VERSION ""

NS_ :

BS_:

BU_:

BO_ 3221225472 VECTOR__INDEPENDENT_SIG_MSG: 0 Vector__XXX
 SG_ current_filter_1 : 0|16@1+ (0.1,-600) [800|4294966496] "" Vector__XXX
 SG_ bms_unique_key_byte7 : 0|8@1+ (1,0) [0|255] "" Vector__XXX
 SG_ bms_unique_key_byte6 : 0|8@1+ (1,0) [0|255] "" Vector__XXX
 SG_ bms_unique_key_byte5 : 0|8@1+ (1,0) [0|255] "" Vector__XXX
 SG_ bms_unique_key_byte4 : 0|8@1+ (1,0) [0|255] "" Vector__XXX
 SG_ bms_unique_key_byte3 : 0|8@1+ (1,0) [0|255] "" Vector__XXX
 SG_ bms_unique_key_byte2 : 0|8@1+ (1,0) [0|255] "" Vector__XXX
 SG_ bms_unique_key_byte1 : 0|8@1+ (1,0) [0|255] "" Vector__XXX
 SG_ bms_unique_key_byte0 : 0|8@1+ (1,0) [0|255] "" Vector__XXX
 SG_ battery_unique_key_byte7 : 0|8@1+ (1,0) [0|255] "" Vector__XXX
 SG_ battery_unique_key_byte6 : 0|8@1+ (1,0) [0|255] "" Vector__XXX
 SG_ battery_unique_key_byte5 : 0|8@1+ (1,0) [0|255] "" Vector__XXX
 SG_ battery_unique_key_byte4 : 0|8@1+ (1,0) [0|255] "" Vector__XXX
 SG_ battery_unique_key_byte3 : 0|8@1+ (1,0) [0|255] "" Vector__XXX
 SG_ battery_unique_key_byte2 : 0|8@1+ (1,0) [0|255] "" Vector__XXX
 SG_ battery_unique_key_byte1 : 0|8@1+ (1,0) [0|255] "" Vector__XXX
 SG_ battery_unique_key_byte0 : 0|8@1+ (1,0) [0|255] "" Vector__XXX
 SG_ slow_charger_state_bms : 0|8@1+ (1,0) [0|255] "" Vector__XXX
 SG_ bms_ota_soc : 0|16@1+ (0.01,0) [0|655.35] "" Vector__XXX
 SG_ hw_minor : 0|8@1+ (1,0) [0|255] "" Vector__XXX
 SG_ hw_major : 0|8@1+ (1,0) [0|255] "" Vector__XXX
 SG_ fw_patch : 0|8@1+ (1,0) [0|255] "" Vector__XXX
 SG_ fw_oem_variant : 0|8@1+ (1,0) [0|255] "" Vector__XXX
 SG_ fw_oem_patch : 0|8@1+ (1,0) [0|255] "" Vector__XXX
 SG_ fw_oem_lookup : 0|8@1+ (1,0) [0|255] "" Vector__XXX
 SG_ fw_minor : 0|8@1+ (1,0) [0|255] "" Vector__XXX
 SG_ fw_major : 0|8@1+ (1,0) [0|255] "" Vector__XXX
 SG_ min_cell_temp_bms : 0|16@1+ (0.01,-100) [150|4294967246] "" Vector__XXX
 SG_ max_cell_temp_bms : 0|16@1+ (0.01,-100) [150|4294967246] "" Vector__XXX
 SG_ min_cell_voltage_bms : 0|16@1+ (0.0001,0) [0|6.5535] "" Vector__XXX
 SG_ max_cell_voltage_bms : 0|16@1+ (0.0001,0) [0|6.5535] "" Vector__XXX
 SG_ tp_alarm : 0|8@1+ (1,0) [0|255] "" Vector__XXX
 SG_ bms_current_bms : 0|16@1+ (0.1,-600) [800|4294966496] "" Vector__XXX
 SG_ dyna_out_accept_2 : 0|8@1+ (1,0) [0|255] "" Vector__XXX
 SG_ dyna_out_accept : 0|8@1+ (1,0) [0|255] "" Vector__XXX
 SG_ dyna_out_2 : 0|16@1+ (1,0) [0|255] "" Vector__XXX
 SG_ stecom_signal_6 : 0|8@1+ (1,0) [0|255] "" Vector__XXX
 SG_ stecom_signal_5 : 0|8@1+ (1,0) [0|255] "" Vector__XXX
 SG_ stecom_signal_4 : 0|8@1+ (1,0) [0|255] "" Vector__XXX
 SG_ stecom_signal_3 : 0|8@1+ (1,0) [0|255] "" Vector__XXX
 SG_ dyna_out_1 : 0|8@1+ (1,0) [0|255] "" Vector__XXX
 SG_ stecom_signal_1 : 0|8@1+ (1,0) [0|255] "" Vector__XXX
 SG_ bms_fault_2 : 0|16@1+ (1,0) [0|65535] "" Vector__XXX
 SG_ bms_fault_1 : 0|16@1+ (1,0) [0|65535] "" Vector__XXX
 SG_ battery_capacity : 0|16@1+ (0.001,0) [0|65.535] "" Vector__XXX
 SG_ used_energy : 0|16@1+ (0.001,0) [0|65.535] "" Vector__XXX
 SG_ io_status : 0|16@1+ (1,0) [0|65535] "" Vector__XXX
 SG_ odo_low : 0|16@1+ (1,0) [0|65535] "" Vector__XXX
 SG_ odo_high : 0|16@1+ (1,0) [0|65535] "" Vector__XXX
 SG_ vehicle_speed : 0|16@1+ (0.01,0) [0|655.35] "" Vector__XXX
 SG_ brake_pedal_position : 0|16@1+ (0.01,0) [0|655.35] "" Vector__XXX
 SG_ throttle_position : 0|16@1+ (0.01,0) [0|655.35] "" Vector__XXX
 SG_ battery_current : 0|16@1+ (0.01,-300) [355.55|4294966996] "" Vector__XXX
 SG_ battery_voltage : 0|16@1+ (0.01,0) [0|655.35] "" Vector__XXX
 SG_ fault_code_1 : 0|16@1+ (1,0) [0|65535] "" Vector__XXX
 SG_ fault_code_2 : 0|16@1+ (1,0) [0|65535] "" Vector__XXX
 SG_ on_off_slow_charger : 0|1@1+ (1,0) [0|1] "" Vector__XXX
 SG_ slow_charger_set_8_bms : 0|8@1+ (1,0) [0|255] "" Vector__XXX
 SG_ slow_charger_set_7_bms : 0|8@1+ (1,0) [0|255] "" Vector__XXX
 SG_ slow_charger_set_6_bms : 0|8@1+ (1,0) [0|255] "" Vector__XXX
 SG_ slow_charger_Set_5_bms : 0|8@1+ (1,0) [0|255] "" Vector__XXX
 SG_ slow_charger_set_4_bms : 0|8@1+ (1,0) [0|255] "" Vector__XXX
 SG_ slow_charger_set_3_bms : 0|8@1+ (1,0) [0|255] "" Vector__XXX
 SG_ slow_charger_set_2_bms : 0|8@1+ (1,0) [0|255] "" Vector__XXX
 SG_ slow_charger_set_1_bms : 0|8@1+ (1,0) [0|255] "" Vector__XXX

BO_ 548 ticm_msg15: 8 Vector__XXX
 SG_ sig_bms_fw_version : 7|16@0+ (1,0) [0|65535] "" Vector__XXX

BO_ 547 ticm_msg14: 8 Vector__XXX
 SG_ sig_bms_hw_version : 7|16@0+ (1,0) [0|65535] "" Vector__XXX

BO_ 526 ticm_msg13: 8 Vector__XXX
 SG_ sig_error_bit : 47|8@0+ (1,0) [0|255] "" Vector__XXX
 SG_ tp_alarm : 7|8@0+ (1,0) [0|255] "" Vector__XXX

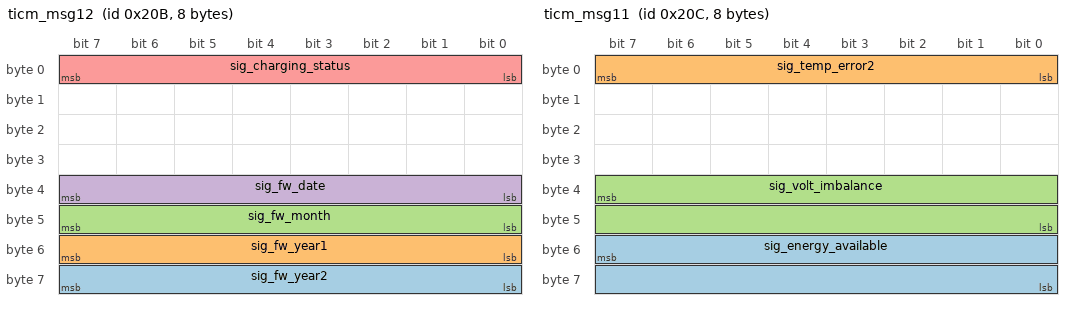
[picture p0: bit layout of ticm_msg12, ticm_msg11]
BO_ 523 ticm_msg12: 8 Vector__XXX
 SG_ sig_fw_year2 : 63|8@0+ (1,0) [0|255] "" Vector__XXX
 SG_ sig_fw_year1 : 55|8@0+ (1,0) [0|255] "" Vector__XXX
 SG_ sig_fw_month : 47|8@0+ (1,0) [0|255] "" Vector__XXX
 SG_ sig_fw_date : 39|8@0+ (1,0) [0|0] "" Vector__XXX
 SG_ sig_charging_status : 7|8@0+ (1,0) [0|255] "" Vector__XXX

BO_ 524 ticm_msg11: 8 Vector__XXX
 SG_ sig_energy_available : 55|16@0+ (1,0) [0|65535] "" Vector__XXX
 SG_ sig_temp_error2 : 7|8@0+ (1,0) [0|255] "" Vector__XXX
 SG_ sig_volt_imbalance : 39|16@0+ (1,0) [0|65535] "" Vector__XXX

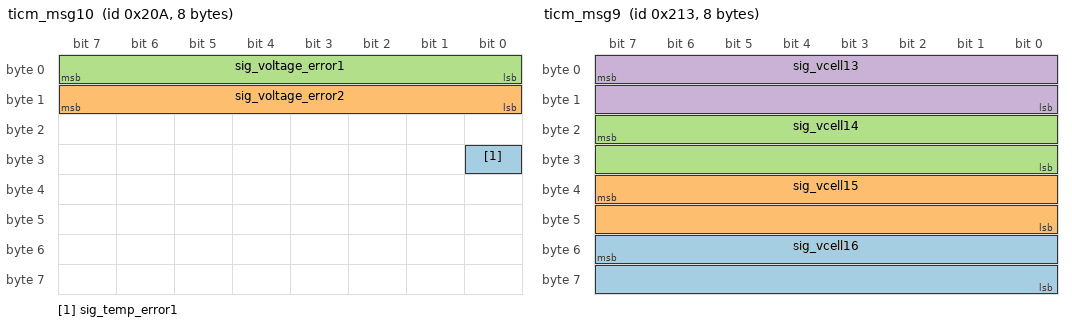
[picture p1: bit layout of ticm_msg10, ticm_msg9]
BO_ 522 ticm_msg10: 8 Vector__XXX
 SG_ sig_temp_error1 : 24|1@0+ (1,0) [0|1] "" Vector__XXX
 SG_ sig_voltage_error2 : 15|8@0+ (1,0) [0|255] "" Vector__XXX
 SG_ sig_voltage_error1 : 7|8@0+ (1,0) [0|255] "" Vector__XXX

BO_ 531 ticm_msg9: 8 Vector__XXX
 SG_ sig_vcell16 : 55|16@0+ (0.001,0) [0|65.535] "" Vector__XXX
 SG_ sig_vcell15 : 39|16@0+ (0.001,0) [0|65.535] "" Vector__XXX
 SG_ sig_vcell14 : 23|16@0+ (0.001,0) [0|65.535] "" Vector__XXX
 SG_ sig_vcell13 : 7|16@0+ (0.001,0) [0|65.535] "" Vector__XXX

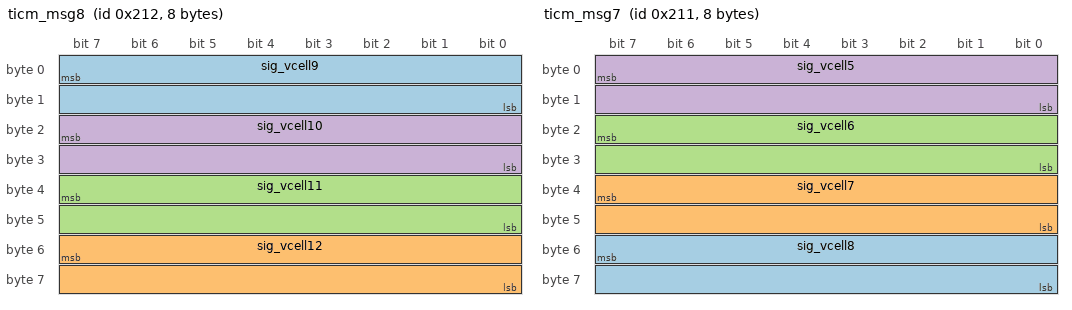
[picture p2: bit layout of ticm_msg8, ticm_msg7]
BO_ 530 ticm_msg8: 8 Vector__XXX
 SG_ sig_vcell9 : 7|16@0+ (0.001,0) [0|65.535] "" Vector__XXX
 SG_ sig_vcell12 : 55|16@0+ (0.001,0) [0|65.535] "" Vector__XXX
 SG_ sig_vcell11 : 39|16@0+ (0.001,0) [0|65.535] "" Vector__XXX
 SG_ sig_vcell10 : 23|16@0+ (0.001,0) [0|65.535] "" Vector__XXX

BO_ 529 ticm_msg7: 8 Vector__XXX
 SG_ sig_vcell8 : 55|16@0+ (0.001,0) [0|65.535] "" Vector__XXX
 SG_ sig_vcell7 : 39|16@0+ (0.001,0) [0|65.535] "" Vector__XXX
 SG_ sig_vcell6 : 23|16@0+ (0.001,0) [0|65.535] "" Vector__XXX
 SG_ sig_vcell5 : 7|16@0+ (0.001,0) [0|65.535] "" Vector__XXX

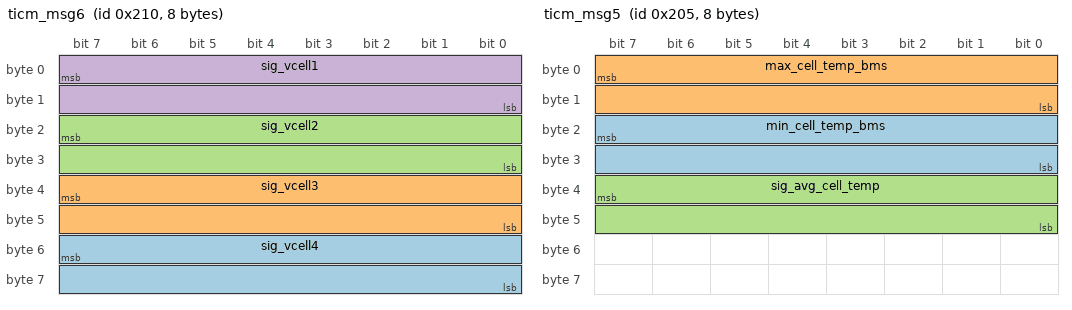
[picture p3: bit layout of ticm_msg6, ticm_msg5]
BO_ 528 ticm_msg6: 8 Vector__XXX
 SG_ sig_vcell4 : 55|16@0+ (0.001,0) [0|65.535] "" Vector__XXX
 SG_ sig_vcell3 : 39|16@0+ (0.001,0) [0|65.535] "" Vector__XXX
 SG_ sig_vcell2 : 23|16@0+ (0.001,0) [0|65.535] "" Vector__XXX
 SG_ sig_vcell1 : 7|16@0+ (0.001,0) [0|65.535] "" Vector__XXX

BO_ 517 ticm_msg5: 8 Vector__XXX
 SG_ min_cell_temp_bms : 23|16@0+ (1.0,0) [0|65535] "" Vector__XXX
 SG_ max_cell_temp_bms : 7|16@0+ (1.0,0) [0|65535] "" Vector__XXX
 SG_ sig_avg_cell_temp : 39|16@0+ (1,0) [0|65535] "" Vector__XXX

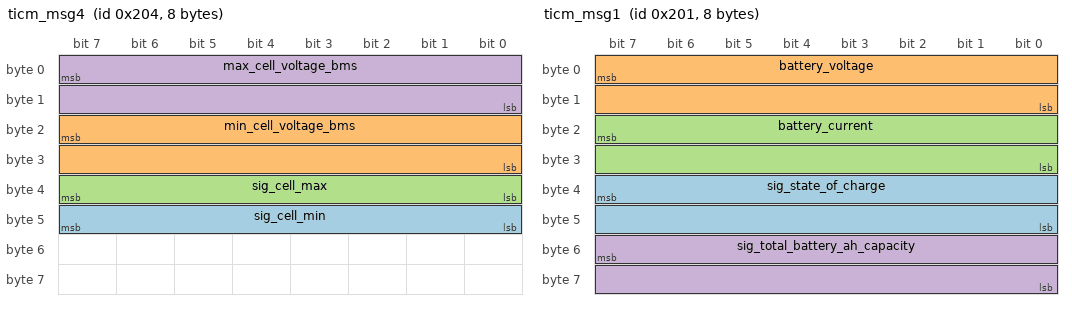
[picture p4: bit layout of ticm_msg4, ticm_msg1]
BO_ 516 ticm_msg4: 8 Vector__XXX
 SG_ sig_cell_min : 47|8@0+ (1,0) [0|255] "" Vector__XXX
 SG_ min_cell_voltage_bms : 23|16@0+ (0.001,0) [0|65.535] "" Vector__XXX
 SG_ sig_cell_max : 39|8@0+ (1,0) [0|255] "" Vector__XXX
 SG_ max_cell_voltage_bms : 7|16@0+ (0.001,0) [0|65.535] "" Vector__XXX

BO_ 515 ticm_msg3: 8 Vector__XXX
 SG_ sig_power_on_status : 31|8@0+ (1,0) [0|255] "" Vector__XXX
 SG_ sig_pack_status : 15|8@0- (1,0) [-128|127] "" Vector__XXX

BO_ 514 ticm_msg2: 8 Vector__XXX
 SG_ sig_soh : 7|16@0+ (1,0) [0|65535] "" Vector__XXX
 SG_ sig_cycle_count : 39|16@0+ (1,0) [0|65535] "" Vector__XXX

BO_ 513 ticm_msg1: 8 Vector__XXX
 SG_ sig_state_of_charge : 39|16@0+ (1,0) [0|65535] "" Vector__XXX
 SG_ battery_voltage : 7|16@0+ (0.001,0) [0|65.535] "" Vector__XXX
 SG_ battery_current : 23|16@0- (1.0,0) [-32768|32767] "" Vector__XXX
 SG_ sig_total_battery_ah_capacity : 55|16@0+ (1,0) [0|65535] "" Vector__XXX

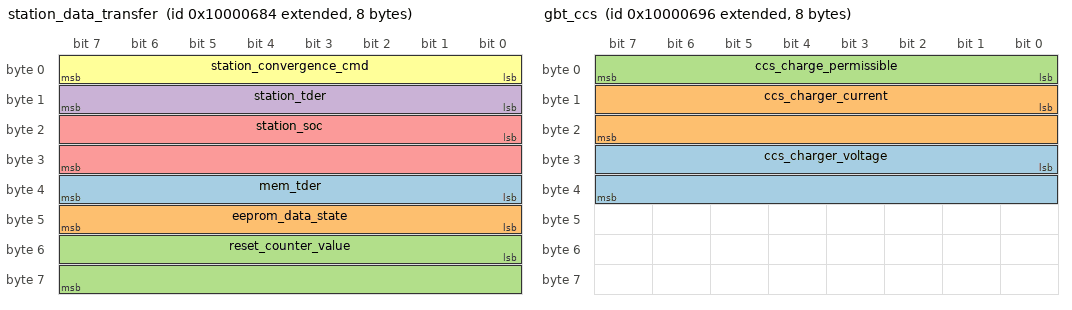
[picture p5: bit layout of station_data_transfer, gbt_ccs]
BO_ 2415920772 station_data_transfer: 8 Vector__XXX
 SG_ mem_tder : 32|8@1+ (1,0) [0|255] "" Vector__XXX
 SG_ eeprom_data_state : 40|8@1+ (1,0) [0|255] "" Vector__XXX
 SG_ reset_counter_value : 48|16@1+ (1,0) [0|65535] "" Vector__XXX
 SG_ station_tder : 8|8@1+ (1,0) [0|0] "" Vector__XXX
 SG_ station_soc : 16|16@1+ (1,0.1) [0.1|65535.1] "" Vector__XXX
 SG_ station_convergence_cmd : 0|8@1+ (1,0) [0|0] "" Vector__XXX

BO_ 2415920790 gbt_ccs: 8 Vector__XXX
 SG_ ccs_charger_voltage : 24|16@1+ (0.1,0) [0|6553.5] "V" Vector__XXX
 SG_ ccs_charger_current : 8|16@1- (0.1,-400) [-3676.8|2876.7] "A" Vector__XXX
 SG_ ccs_charge_permissible : 0|8@1+ (1,0) [0|255] "" Vector__XXX

BO_ 2415920785 gbt_bst_cst: 8 Vector__XXX
 SG_ cst_byte3 : 56|8@1+ (1,0) [0|255] "" Vector__XXX
 SG_ cst_byte2 : 48|8@1+ (1,0) [0|255] "" Vector__XXX
 SG_ csr_byte1 : 40|8@1+ (1,0) [0|255] "" Vector__XXX
 SG_ cst_byte0 : 32|8@1+ (1,0) [0|255] "" Vector__XXX
 SG_ bst_voltage_error : 26|2@1+ (1,0) [0|3] "" Vector__XXX
 SG_ bst_voltage_detection_fault : 20|2@1+ (1,0) [0|3] "" Vector__XXX
 SG_ bst_soc_cause : 0|2@1+ (1,0) [0|3] "" Vector__XXX
 SG_ bst_pack_voltage_cause : 2|2@1+ (1,0) [0|3] "" Vector__XXX
 SG_ bst_output_connector_ot_fault : 10|2@1+ (1,0) [0|3] "" Vector__XXX
 SG_ bst_other_fault : 22|2@1+ (1,0) [0|3] "" Vector__XXX
 SG_ bst_max_cell_volt_cause : 4|2@1+ (1,0) [0|3] "" Vector__XXX
 SG_ bst_insulation_fault : 8|2@1+ (1,0) [0|3] "" Vector__XXX
 SG_ bst_hv_relay_fault : 18|2@1+ (1,0) [0|3] "" Vector__XXX
 SG_ bst_current_error : 24|2@1+ (1,0) [0|3] "" Vector__XXX
 SG_ bst_cst_cause : 6|2@1+ (1,0) [0|3] "" Vector__XXX
 SG_ bst_charging_connector_fault : 14|2@1+ (1,0) [0|3] "" Vector__XXX
 SG_ bst_bms_component_fault : 12|2@1+ (1,0) [0|3] "" Vector__XXX
 SG_ bst_battery_ot_fault : 16|2@1+ (1,0) [0|3] "" Vector__XXX

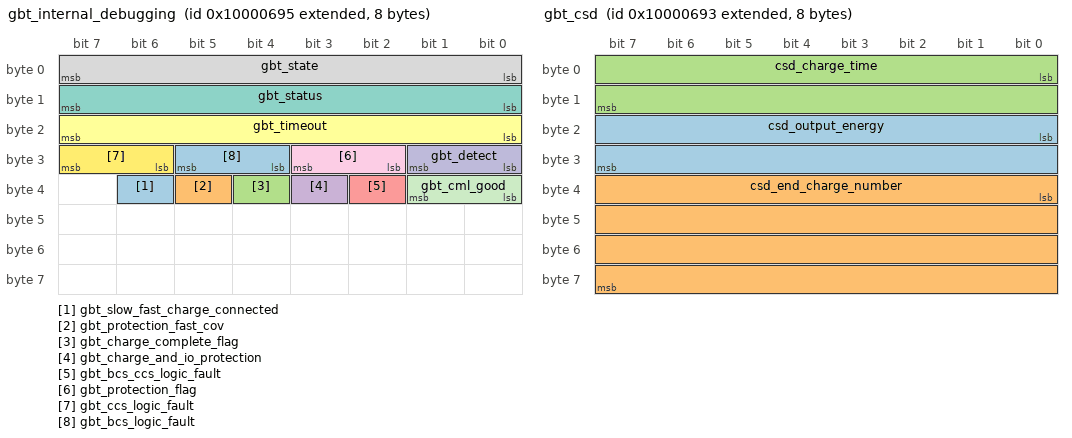
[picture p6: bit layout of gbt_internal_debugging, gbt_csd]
BO_ 2415920789 gbt_internal_debugging: 8 Vector__XXX
 SG_ gbt_slow_fast_charge_connected : 38|1@1+ (1,0) [0|1] "" Vector__XXX
 SG_ gbt_protection_fast_cov : 37|1@1+ (1,0) [0|1] "" Vector__XXX
 SG_ gbt_charge_complete_flag : 36|1@1+ (1,0) [0|1] "" Vector__XXX
 SG_ gbt_charge_and_io_protection : 35|1@1+ (1,0) [0|1] "" Vector__XXX
 SG_ gbt_bcs_ccs_logic_fault : 34|1@1+ (1,0) [0|0] "" Vector__XXX
 SG_ gbt_timeout : 16|8@1+ (1,0) [0|255] "" Vector__XXX
 SG_ gbt_status : 8|8@1+ (1,0) [0|255] "" Vector__XXX
 SG_ gbt_state : 0|8@1+ (1,0) [0|255] "" Vector__XXX
 SG_ gbt_protection_flag : 26|2@1+ (1,0) [0|3] "" Vector__XXX
 SG_ gbt_detect : 24|2@1+ (1,0) [0|3] "" Vector__XXX
 SG_ gbt_cml_good : 32|2@1+ (1,0) [0|3] "" Vector__XXX
 SG_ gbt_ccs_logic_fault : 30|2@1+ (1,0) [0|3] "" Vector__XXX
 SG_ gbt_bcs_logic_fault : 28|2@1+ (1,0) [0|3] "" Vector__XXX

BO_ 2415920787 gbt_csd: 8 Vector__XXX
 SG_ csd_output_energy : 16|16@1+ (0.1,0) [0|6553.5] "" Vector__XXX
 SG_ csd_end_charge_number : 32|32@1+ (1,0) [0|4294967295] "" Vector__XXX
 SG_ csd_charge_time : 0|16@1+ (1,0) [0|65535] "" Vector__XXX

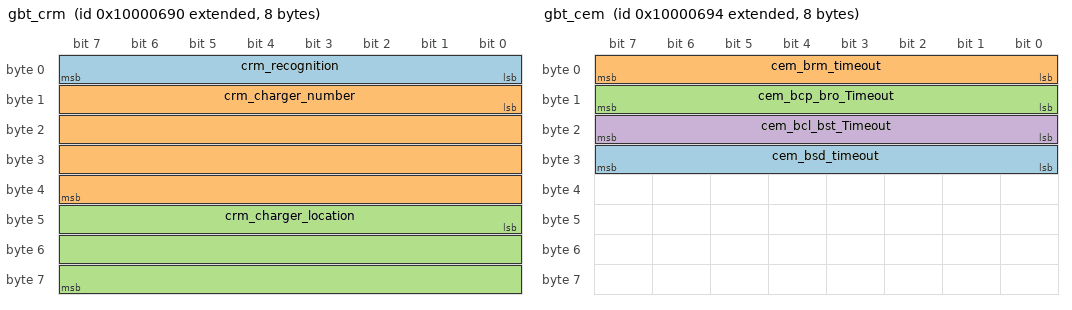
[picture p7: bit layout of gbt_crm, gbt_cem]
BO_ 2415920784 gbt_crm: 8 Vector__XXX
 SG_ crm_recognition : 0|8@1+ (1,0) [0|255] "" Vector__XXX
 SG_ crm_charger_number : 8|32@1+ (1,0) [0|4294967295] "" Vector__XXX
 SG_ crm_charger_location : 40|24@1+ (1,0) [0|16777215] "" Vector__XXX

BO_ 2415920788 gbt_cem: 8 Vector__XXX
 SG_ cem_bsd_timeout : 24|8@1+ (1,0) [0|255] "" Vector__XXX
 SG_ cem_brm_timeout : 0|8@1+ (1,0) [0|255] "" Vector__XXX
 SG_ cem_bcp_bro_Timeout : 8|8@1+ (1,0) [0|255] "" Vector__XXX
 SG_ cem_bcl_bst_Timeout : 16|8@1+ (1,0) [0|255] "" Vector__XXX

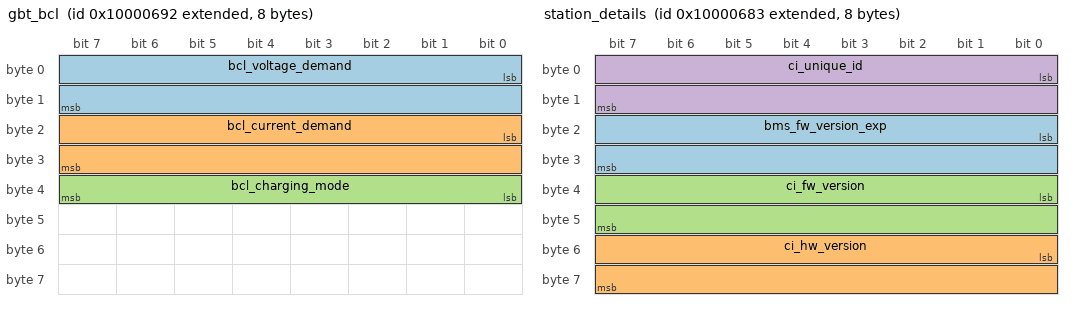
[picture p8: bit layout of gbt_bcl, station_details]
BO_ 2415920786 gbt_bcl: 8 Vector__XXX
 SG_ bcl_voltage_demand : 0|16@1+ (0.1,0) [0|6553.5] "" Vector__XXX
 SG_ bcl_current_demand : 16|16@1+ (0.1,-40) [6513.5|4294967256] "" Vector__XXX
 SG_ bcl_charging_mode : 32|8@1+ (1,0) [0|255] "" Vector__XXX

BO_ 2415920771 station_details: 8 Vector__XXX
 SG_ bms_fw_version_exp : 16|16@1+ (1,0) [0|65535] "" Vector__XXX
 SG_ ci_hw_version : 48|16@1+ (1,0) [0|65535] "" Vector__XXX
 SG_ ci_fw_version : 32|16@1+ (1,0) [0|65535] "" Vector__XXX
 SG_ ci_unique_id : 0|16@1+ (1,0) [0|65535] "" Vector__XXX

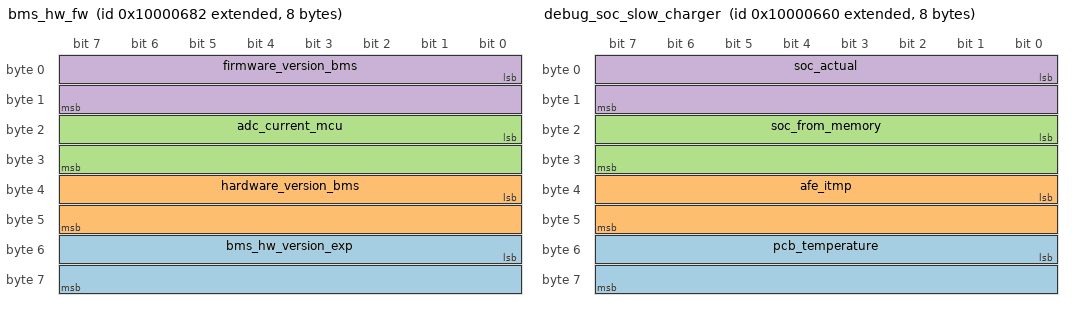
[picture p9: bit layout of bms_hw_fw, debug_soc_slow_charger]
BO_ 2415920770 bms_hw_fw: 8 Vector__XXX
 SG_ bms_hw_version_exp : 48|16@1+ (1,0) [0|65535] "" Vector__XXX
 SG_ hardware_version_bms : 32|16@1+ (1,0) [0|65535] "" Vector__XXX
 SG_ adc_current_mcu : 16|16@1+ (1,0) [0|65535] "" Vector__XXX
 SG_ firmware_version_bms : 0|16@1+ (1,0) [0|65535] "" Vector__XXX

BO_ 2415920769 bms_unique_Key: 8 Vector__XXX
 SG_ bms_unique_key : 0|64@1+ (1,0) [0|1.8446744074E+019] "" Vector__XXX

BO_ 2415920736 debug_soc_slow_charger: 8 Vector__XXX
 SG_ pcb_temperature : 48|16@1+ (0.01,-100) [555.35|4294967196] "" Vector__XXX
 SG_ afe_itmp : 32|16@1+ (0.01,-100) [555.35|4294967196] "" Vector__XXX
 SG_ soc_from_memory : 16|16@1+ (1,0) [0|65535] "" Vector__XXX
 SG_ soc_actual : 0|16@1+ (0.01,0) [0|150] "" Vector__XXX

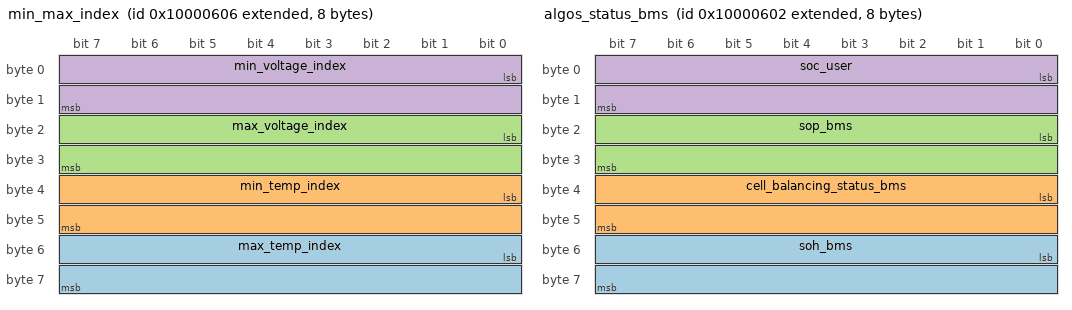
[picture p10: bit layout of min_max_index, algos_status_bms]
BO_ 2415920646 min_max_index: 8 Vector__XXX
 SG_ max_temp_index : 48|16@1+ (1,0) [0|65535] "" Vector__XXX
 SG_ min_temp_index : 32|16@1+ (1,0) [0|65535] "" Vector__XXX
 SG_ max_voltage_index : 16|16@1+ (1,0) [0|65535] "" Vector__XXX
 SG_ min_voltage_index : 0|16@1+ (1,0) [0|65535] "" Vector__XXX

BO_ 2415920647 history_of_protections: 8 Vector__XXX
 SG_ reset_cause : 48|16@1+ (1,0) [0|65535] "" Vector__XXX
 SG_ ib1_bms_hist : 20|1@1+ (1,0) [0|0] "" Vector__XXX
 SG_ ccov_bms_hist : 19|1@1+ (1,0) [0|1] "" Vector__XXX
 SG_ sc_coc1_bms_hist : 18|1@1+ (1,0) [0|1] "" Vector__XXX
 SG_ ccuv_bms_hist : 17|1@1+ (1,0) [0|1] "" Vector__XXX
 SG_ icp_hist : 16|1@1+ (1,0) [0|1] "" Vector__XXX
 SG_ sc_coc_bms_hist : 15|1@1+ (1,0) [0|1] "" Vector__XXX
 SG_ roc_bms_hist : 14|1@1+ (1,0) [0|1] "" Vector__XXX
 SG_ ib_bms_hist : 11|1@1+ (1,0) [0|0] "" Vector__XXX
 SG_ scf_bms_hist : 13|1@1+ (1,0) [0|1] "" Vector__XXX
 SG_ tso_bms_hist : 12|1@1+ (1,0) [0|0] "" Vector__XXX
 SG_ cso_bms_hist : 10|1@1+ (1,0) [0|0] "" Vector__XXX
 SG_ dut_bms_hist : 9|1@1+ (1,0) [0|0] "" Vector__XXX
 SG_ cut_bms_hist : 8|1@1+ (1,0) [0|0] "" Vector__XXX
 SG_ dot_bms_hist : 7|1@1+ (1,0) [0|0] "" Vector__XXX
 SG_ cot_bms_hist : 6|1@1+ (1,0) [0|0] "" Vector__XXX
 SG_ doc_bms_hist : 5|1@1+ (1,0) [0|0] "" Vector__XXX
 SG_ coc_bms_hist : 4|1@1+ (1,0) [0|0] "" Vector__XXX
 SG_ puv_bms_hist : 3|1@1+ (1,0) [0|0] "" Vector__XXX
 SG_ pov_bms_hist : 2|1@1+ (1,0) [0|0] "" Vector__XXX
 SG_ cuv_bms_hist : 1|1@1+ (1,0) [0|0] "" Vector__XXX
 SG_ cov_bms_hist : 0|1@1+ (1,0) [0|0] "" Vector__XXX

BO_ 2415920768 battery_unique_key: 8 Vector__XXX
 SG_ battery_unique_key : 0|64@1+ (1,0) [0|1.8446744074E+019] "" Vector__XXX

BO_ 2415920642 algos_status_bms: 8 Vector__XXX
 SG_ soh_bms : 48|16@1+ (0.01,0) [0|150] "" Vector__XXX
 SG_ cell_balancing_status_bms : 32|16@1+ (1,0) [0|65535] "" Vector__XXX
 SG_ sop_bms : 16|16@1+ (1,0) [0|250] "" Vector__XXX
 SG_ soc_user : 0|16@1+ (0.01,0) [0|150] "" Vector__XXX

BO_ 2415920641 safety_status_bms: 8 Vector__XXX
 SG_ ib1_bms_flag : 52|1@1+ (1,0) [0|1] "" Vector__XXX
 SG_ ib1_bms : 20|1@1+ (1,0) [0|1] "" Vector__XXX
 SG_ ccov_flag_bms : 51|1@1+ (1,0) [0|1] "" Vector__XXX
 SG_ ccov_bms : 19|1@1+ (1,0) [0|1] "" Vector__XXX
 SG_ sc_coc1_flag_bms : 50|1@1+ (1,0) [0|1] "" Vector__XXX
 SG_ sc_coc1_bms : 18|1@1+ (1,0) [0|1] "" Vector__XXX
 SG_ ccuv_flag_bms : 49|1@1+ (1,0) [0|1] "" Vector__XXX
 SG_ ccuv_bms : 17|1@1+ (1,0) [0|1] "" Vector__XXX
 SG_ icp_flag : 48|1@1+ (1,0) [0|1] "" Vector__XXX
 SG_ icp_status : 16|1@1+ (1,0) [0|1] "" Vector__XXX
 SG_ sc_coc_flag_bms : 47|1@1+ (1,0) [0|1] "" Vector__XXX
 SG_ sc_coc_bms : 15|1@1+ (1,0) [0|1] "" Vector__XXX
 SG_ roc_flag_bms : 46|1@1+ (1,0) [0|1] "" Vector__XXX
 SG_ roc_bms : 14|1@1+ (1,0) [0|1] "" Vector__XXX
 SG_ ib_bms_flag : 43|1@1+ (1,0) [0|1] "" Vector__XXX
 SG_ ib_bms : 11|1@1+ (1,0) [0|1] "" Vector__XXX
 SG_ scf_flag_bms : 45|1@1+ (1,0) [0|1] "" Vector__XXX
 SG_ tso_flag_bms : 44|1@1+ (1,0) [0|1] "" Vector__XXX
 SG_ cso_flag_bms : 42|1@1+ (1,0) [0|1] "" Vector__XXX
 SG_ dut_flag_bms : 41|1@1+ (1,0) [0|1] "" Vector__XXX
 SG_ cut_flag_bms : 40|1@1+ (1,0) [0|1] "" Vector__XXX
 SG_ dot_flag_bms : 39|1@1+ (1,0) [0|1] "" Vector__XXX
 SG_ cot_flag_bms : 38|1@1+ (1,0) [0|1] "" Vector__XXX
 SG_ doc_flag_bms : 37|1@1+ (1,0) [0|1] "" Vector__XXX
 SG_ coc_flag_bms : 36|1@1+ (1,0) [0|1] "" Vector__XXX
 SG_ puv_flag_bms : 35|1@1+ (1,0) [0|1] "" Vector__XXX
 SG_ pov_flag_bms : 34|1@1+ (1,0) [0|1] "" Vector__XXX
 SG_ cuv_flag_bms : 33|1@1+ (1,0) [0|1] "" Vector__XXX
 SG_ cov_flag_bms : 32|1@1+ (1,0) [0|1] "" Vector__XXX
 SG_ scf_bms : 13|1@1+ (1,0) [0|1] "" Vector__XXX
 SG_ tso_bms : 12|1@1+ (1,0) [0|1] "" Vector__XXX
 SG_ cso_bms : 10|1@1+ (1,0) [0|1] "" Vector__XXX
 SG_ dut_bms : 9|1@1+ (1,0) [0|1] "" Vector__XXX
 SG_ cut_bms : 8|1@1+ (1,0) [0|1] "" Vector__XXX
 SG_ dot_bms : 7|1@1+ (1,0) [0|1] "" Vector__XXX
 SG_ cot_bms : 6|1@1+ (1,0) [0|1] "" Vector__XXX
 SG_ doc_bms : 5|1@1+ (1,0) [0|1] "" Vector__XXX
 SG_ coc_bms : 4|1@1+ (1,0) [0|1] "" Vector__XXX
 SG_ puv_bms : 3|1@1+ (1,0) [0|1] "" Vector__XXX
 SG_ pov_bms : 2|1@1+ (1,0) [0|1] "" Vector__XXX
 SG_ cuv_bms : 1|1@1+ (1,0) [0|1] "" Vector__XXX
 SG_ cov_bms : 0|1@1+ (1,0) [0|1] "" Vector__XXX

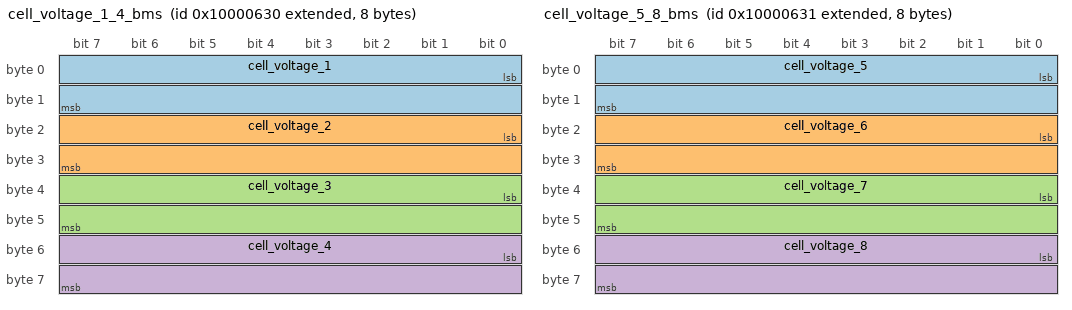
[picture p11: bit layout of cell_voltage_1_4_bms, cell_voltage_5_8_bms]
BO_ 2415920688 cell_voltage_1_4_bms: 8 Vector__XXX
 SG_ cell_voltage_1 : 0|16@1+ (0.0001,0) [0|6.5535] "" Vector__XXX
 SG_ cell_voltage_2 : 16|16@1+ (0.0001,0) [0|6.5535] "" Vector__XXX
 SG_ cell_voltage_3 : 32|16@1+ (0.0001,0) [0|6.5535] "" Vector__XXX
 SG_ cell_voltage_4 : 48|16@1+ (0.0001,0) [0|6.5535] "" Vector__XXX

BO_ 2415920689 cell_voltage_5_8_bms: 8 Vector__XXX
 SG_ cell_voltage_5 : 0|16@1+ (0.0001,0) [0|6.5535] "" Vector__XXX
 SG_ cell_voltage_6 : 16|16@1+ (0.0001,0) [0|6.5535] "" Vector__XXX
 SG_ cell_voltage_7 : 32|16@1+ (0.0001,0) [0|6.5535] "" Vector__XXX
 SG_ cell_voltage_8 : 48|16@1+ (0.0001,0) [0|6.5535] "" Vector__XXX

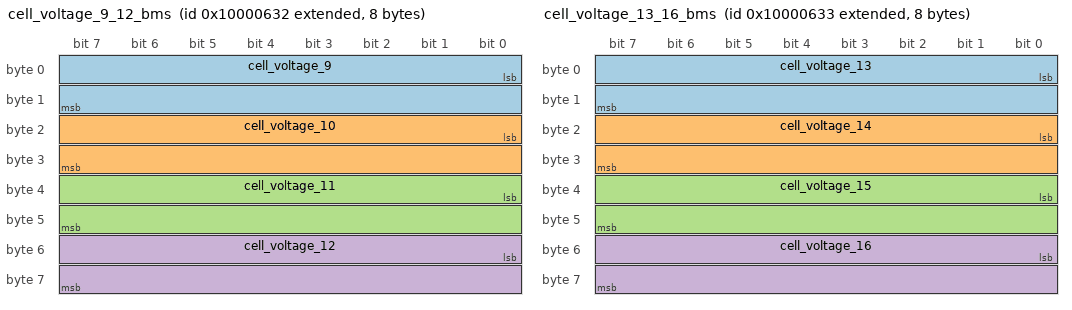
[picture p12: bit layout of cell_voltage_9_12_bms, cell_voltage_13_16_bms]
BO_ 2415920690 cell_voltage_9_12_bms: 8 Vector__XXX
 SG_ cell_voltage_9 : 0|16@1+ (0.0001,0) [0|6.5535] "" Vector__XXX
 SG_ cell_voltage_10 : 16|16@1+ (0.0001,0) [0|6.5535] "" Vector__XXX
 SG_ cell_voltage_11 : 32|16@1+ (0.0001,0) [0|6.5535] "" Vector__XXX
 SG_ cell_voltage_12 : 48|16@1+ (0.0001,0) [0|6.5535] "" Vector__XXX

BO_ 2415920691 cell_voltage_13_16_bms: 8 Vector__XXX
 SG_ cell_voltage_13 : 0|16@1+ (0.0001,0) [0|6.5535] "" Vector__XXX
 SG_ cell_voltage_14 : 16|16@1+ (0.0001,0) [0|6.5535] "" Vector__XXX
 SG_ cell_voltage_15 : 32|16@1+ (0.0001,0) [0|6.5535] "" Vector__XXX
 SG_ cell_voltage_16 : 48|16@1+ (0.0001,0) [0|6.5535] "" Vector__XXX

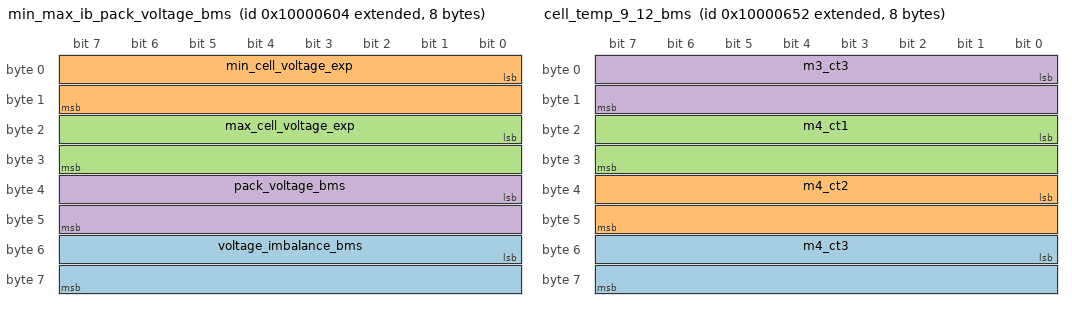
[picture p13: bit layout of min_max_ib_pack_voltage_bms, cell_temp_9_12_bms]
BO_ 2415920644 min_max_ib_pack_voltage_bms: 8 Vector__XXX
 SG_ voltage_imbalance_bms : 48|16@1+ (0.0001,0) [0|6.5535] "" Vector__XXX
 SG_ min_cell_voltage_exp : 0|16@1+ (0.0001,0) [0|6.5535] "" Vector__XXX
 SG_ max_cell_voltage_exp : 16|16@1+ (0.0001,0) [0|6.5535] "" Vector__XXX
 SG_ pack_voltage_bms : 32|16@1+ (0.01,0) [0|65] "" Vector__XXX

BO_ 2415920722 cell_temp_9_12_bms: 8 Vector__XXX
 SG_ m4_ct3 : 48|16@1+ (0.01,-100) [555.35|4294967196] "C" Vector__XXX
 SG_ m4_ct2 : 32|16@1+ (0.01,-100) [555.35|4294967196] "C" Vector__XXX
 SG_ m4_ct1 : 16|16@1+ (0.01,-100) [555.35|4294967196] "C" Vector__XXX
 SG_ m3_ct3 : 0|16@1+ (0.01,-100) [555.35|4294967196] "C" Vector__XXX

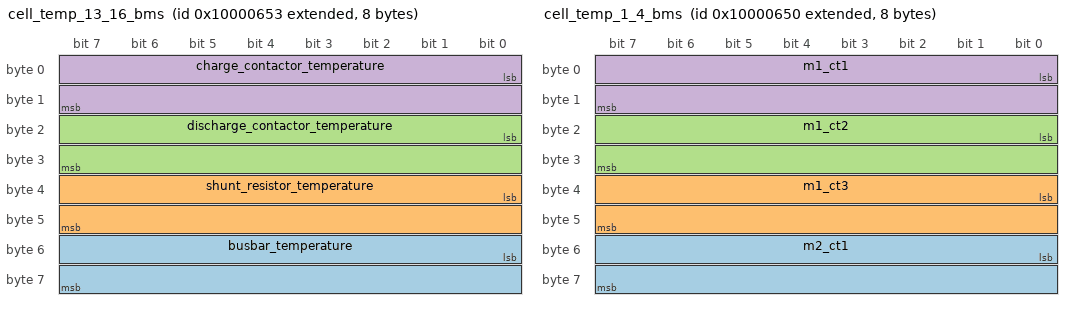
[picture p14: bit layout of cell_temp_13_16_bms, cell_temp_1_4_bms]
BO_ 2415920723 cell_temp_13_16_bms: 8 Vector__XXX
 SG_ busbar_temperature : 48|16@1+ (0.01,-100) [555.35|4294967196] "C" Vector__XXX
 SG_ shunt_resistor_temperature : 32|16@1+ (0.01,-100) [555.35|4294967196] "C" Vector__XXX
 SG_ discharge_contactor_temperature : 16|16@1+ (0.01,-100) [555.35|4294967196] "C" Vector__XXX
 SG_ charge_contactor_temperature : 0|16@1+ (0.01,-100) [555.35|4294967196] "C" Vector__XXX

BO_ 2415920720 cell_temp_1_4_bms: 8 Vector__XXX
 SG_ m2_ct1 : 48|16@1+ (0.01,-100) [555.35|4294967196] "C" Vector__XXX
 SG_ m1_ct3 : 32|16@1+ (0.01,-100) [555.35|4294967196] "C" Vector__XXX
 SG_ m1_ct2 : 16|16@1+ (0.01,-100) [555.35|4294967196] "C" Vector__XXX
 SG_ m1_ct1 : 0|16@1+ (0.01,-100) [555.35|4294967196] "C" Vector__XXX

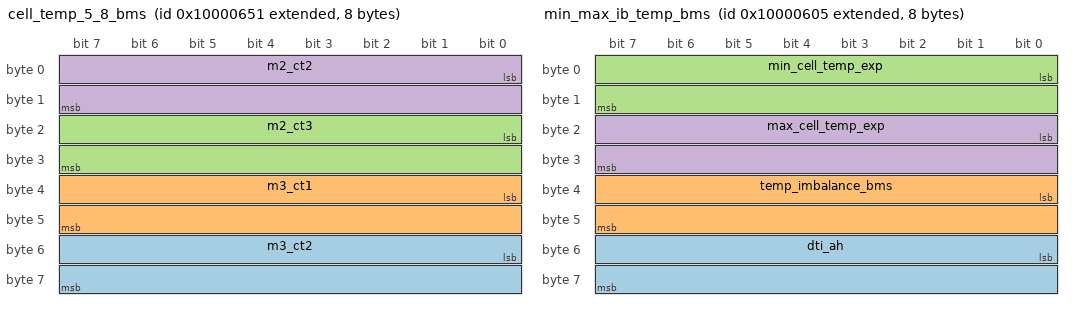
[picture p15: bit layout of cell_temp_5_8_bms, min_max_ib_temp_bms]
BO_ 2415920721 cell_temp_5_8_bms: 8 Vector__XXX
 SG_ m3_ct2 : 48|16@1+ (0.01,-100) [555.35|4294967196] "C" Vector__XXX
 SG_ m3_ct1 : 32|16@1+ (0.01,-100) [555.35|4294967196] "C" Vector__XXX
 SG_ m2_ct3 : 16|16@1+ (0.01,-100) [555.35|4294967196] "C" Vector__XXX
 SG_ m2_ct2 : 0|16@1+ (0.01,-100) [555.35|4294967196] "C" Vector__XXX

BO_ 2415920645 min_max_ib_temp_bms: 8 Vector__XXX
 SG_ dti_ah : 48|16@1+ (0.1,0) [0|6553.5] "" Vector__XXX
 SG_ temp_imbalance_bms : 32|16@1+ (0.01,-100) [150|4294967246] "" Vector__XXX
 SG_ min_cell_temp_exp : 0|16@1+ (0.01,-100) [150|4294967246] "" Vector__XXX
 SG_ max_cell_temp_exp : 16|16@1+ (0.01,-100) [150|4294967246] "" Vector__XXX

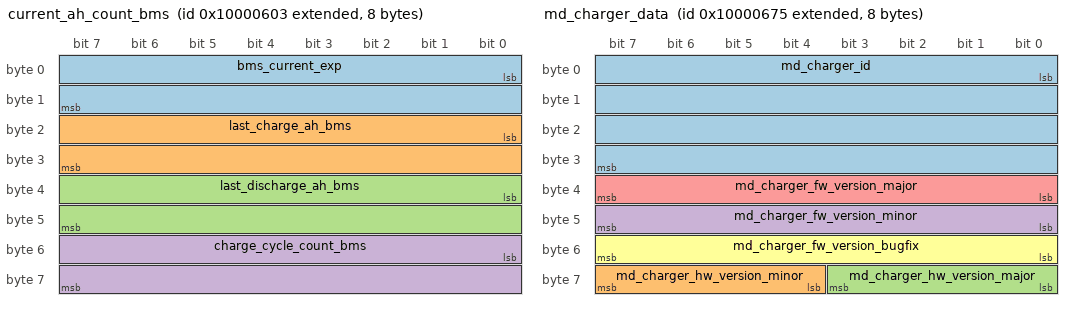
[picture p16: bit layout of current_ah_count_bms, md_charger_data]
BO_ 2415920643 current_ah_count_bms: 8 Vector__XXX
 SG_ bms_current_exp : 0|16@1+ (0.1,-600) [800|4294966496] "" Vector__XXX
 SG_ last_charge_ah_bms : 16|16@1+ (0.1,0) [0|250] "" Vector__XXX
 SG_ last_discharge_ah_bms : 32|16@1+ (0.1,0) [0|250] "" Vector__XXX
 SG_ charge_cycle_count_bms : 48|16@1+ (0.1,0) [0|5000] "" Vector__XXX

BO_ 2415920640 sateflow_status_bms: 8 Vector__XXX
 SG_ gun_unlock_retry_count : 60|4@1+ (1,0) [0|15] "" Vector__XXX
 SG_ gun_lock_retry_count : 56|4@1+ (1,0) [0|15] "" Vector__XXX
 SG_ tp_warning : 13|1@1+ (1,0) [0|1] "" Vector__XXX
 SG_ dot_warning : 12|1@1+ (1,0) [0|1] "" Vector__XXX
 SG_ tp_alarm_exp : 11|1@1+ (1,0) [0|1] "" Vector__XXX
 SG_ solenoid_feedback : 53|1@1+ (1,0) [0|1] "" Vector__XXX
 SG_ gun_unlock_status : 50|1@1+ (1,0) [0|1] "" Vector__XXX
 SG_ gun_unlock_failed : 51|1@1+ (1,0) [0|1] "" Vector__XXX
 SG_ gun_lock_status : 48|1@1+ (1,0) [0|1] "" Vector__XXX
 SG_ gun_lock_req : 52|1@1+ (1,0) [0|1] "" Vector__XXX
 SG_ gun_lock_failed : 49|1@1+ (1,0) [0|1] "" Vector__XXX
 SG_ cc_on_req : 39|1@1+ (1,0) [0|1] "" Vector__XXX
 SG_ shutdown_flag_3 : 26|1@1+ (1,0) [0|1] "" Vector__XXX
 SG_ shutdown_flag_2 : 25|1@1+ (1,0) [0|1] "" Vector__XXX
 SG_ shutdown_flag_1 : 24|1@1+ (1,0) [0|1] "" Vector__XXX
 SG_ charge_complete_status : 10|1@1+ (1,0) [0|1] "" Vector__XXX
 SG_ motor_enable_out_bms : 38|1@1+ (1,0) [0|1] "" Vector__XXX
 SG_ discharge_precharge_out_bms : 36|1@1+ (1,0) [0|1] "" Vector__XXX
 SG_ discharge_contactor_out_bms : 37|1@1+ (1,0) [0|1] "" Vector__XXX
 SG_ charge_precharge_out_bms : 34|1@1+ (1,0) [0|1] "" Vector__XXX
 SG_ charge_contactor_out_bms : 35|1@1+ (1,0) [0|1] "" Vector__XXX
 SG_ proximity_pilot_in_bms : 33|1@1+ (1,0) [0|1] "" Vector__XXX
 SG_ key_in_bms : 32|1@1+ (1,0) [0|1] "" Vector__XXX
 SG_ fast_charger_detected_bms : 9|1@1+ (1,0) [0|1] "" Vector__XXX
 SG_ slow_charger_detected_bms : 8|1@1+ (1,0) [0|1] "" Vector__XXX
 SG_ battery_state_bms : 16|8@1+ (1,0) [0|4] "" Vector__XXX
 SG_ discharge_path_status_bms : 7|1@1+ (1,0) [0|1] "" Vector__XXX
 SG_ charge_path_status_bms : 6|1@1+ (1,0) [0|1] "" Vector__XXX
 SG_ discharge_pf_ok_bms : 5|1@1+ (1,0) [0|1] "" Vector__XXX
 SG_ charge_pf_ok_bms : 4|1@1+ (1,0) [0|1] "" Vector__XXX
 SG_ discharge_io_ok_bms : 3|1@1+ (1,0) [0|1] "" Vector__XXX
 SG_ charge_io_ok_bms : 2|1@1+ (1,0) [0|1] "" Vector__XXX
 SG_ discharge_protection_ok_bms : 1|1@1+ (1,0) [0|1] "" Vector__XXX
 SG_ charge_protection_ok_bms : 0|1@1+ (1,0) [0|1] "" Vector__XXX

BO_ 2415920757 md_charger_data: 8 Vector__XXX
 SG_ md_charger_id : 0|32@1+ (1,0) [2147483647|2147483648] "" Vector__XXX
 SG_ md_charger_hw_version_minor : 60|4@1+ (1,0) [0|15] "" Vector__XXX
 SG_ md_charger_hw_version_major : 56|4@1+ (1,0) [0|15] "" Vector__XXX
 SG_ md_charger_fw_version_minor : 40|8@1+ (1,0) [0|255] "" Vector__XXX
 SG_ md_charger_fw_version_major : 32|8@1+ (1,0) [0|255] "" Vector__XXX
 SG_ md_charger_fw_version_bugfix : 48|8@1+ (1,0) [0|255] "" Vector__XXX

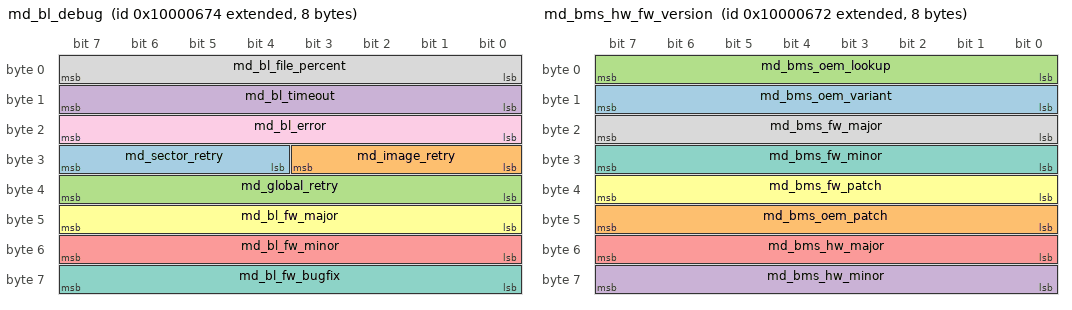
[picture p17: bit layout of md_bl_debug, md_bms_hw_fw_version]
BO_ 2415920756 md_bl_debug: 8 Vector__XXX
 SG_ md_sector_retry : 28|4@1+ (1,0) [0|15] "" Vector__XXX
 SG_ md_image_retry : 24|4@1+ (1,0) [0|15] "" Vector__XXX
 SG_ md_global_retry : 32|8@1+ (1,0) [0|255] "" Vector__XXX
 SG_ md_bl_timeout : 8|8@1+ (1,0) [0|255] "" Vector__XXX
 SG_ md_bl_fw_minor : 48|8@1+ (1,0) [0|255] "" Vector__XXX
 SG_ md_bl_fw_major : 40|8@1+ (1,0) [0|255] "" Vector__XXX
 SG_ md_bl_fw_bugfix : 56|8@1+ (1,0) [0|255] "" Vector__XXX
 SG_ md_bl_file_percent : 0|8@1+ (1,0) [0|255] "" Vector__XXX
 SG_ md_bl_error : 16|8@1+ (1,0) [0|255] "" Vector__XXX

BO_ 2415920755 md_soc_cycle_count: 8 Vector__XXX
 SG_ md_cycle_count : 32|32@1- (1,0) [-3.4E+038|3.4E+038] "" Vector__XXX
 SG_ md_soc : 0|32@1- (1,0) [-3.4E+038|3.4E+038] "" Vector__XXX

BO_ 2415920754 md_bms_hw_fw_version: 8 Vector__XXX
 SG_ md_bms_oem_variant : 8|8@1+ (1,0) [0|255] "" Vector__XXX
 SG_ md_bms_oem_patch : 40|8@1+ (1,0) [0|255] "" Vector__XXX
 SG_ md_bms_oem_lookup : 0|8@1+ (1,0) [0|255] "" Vector__XXX
 SG_ md_bms_hw_minor : 56|8@1+ (1,0) [0|255] "" Vector__XXX
 SG_ md_bms_hw_major : 48|8@1+ (1,0) [0|255] "" Vector__XXX
 SG_ md_bms_fw_patch : 32|8@1+ (1,0) [0|255] "" Vector__XXX
 SG_ md_bms_fw_minor : 24|8@1+ (1,0) [0|255] "" Vector__XXX
 SG_ md_bms_fw_major : 16|8@1+ (1,0) [0|255] "" Vector__XXX

BO_ 2415920753 md_battery_unique_key: 8 Vector__XXX
 SG_ md_battery_unique_key : 0|64@1+ (1,0) [0|1.8446744074E+019] "" Vector__XXX

BO_ 2415920752 md_status: 8 Vector__XXX
 SG_ md_motor_disable : 8|8@1+ (1,0) [0|255] "" Vector__XXX
 SG_ md_image_present : 0|8@1+ (1,0) [0|255] "" Vector__XXX

BO_ 779 sc_cem_msg: 8 Vector__XXX
 SG_ charger_receive_timeout : 0|8@1+ (1,0) [0|255] "" Vector__XXX
 SG_ charger_error_cause : 8|16@1+ (1,0) [0|65535] "" Vector__XXX

BO_ 778 sc_bem_msg: 8 Vector__XXX
 SG_ bms_receive_timeout : 0|8@1+ (1,0) [0|255] "" Vector__XXX
 SG_ bms_charging_error_cause : 8|16@1+ (1,0) [0|255] "" Vector__XXX

BO_ 777 sc_cst_msg: 8 Vector__XXX
 SG_ bms_stop_charging_reason : 0|8@1+ (1,0) [0|255] "" Vector__XXX

BO_ 776 sc_bst_msg: 8 Vector__XXX
 SG_ charger_stop_reason : 0|8@1+ (1,0) [0|255] "" Vector__XXX

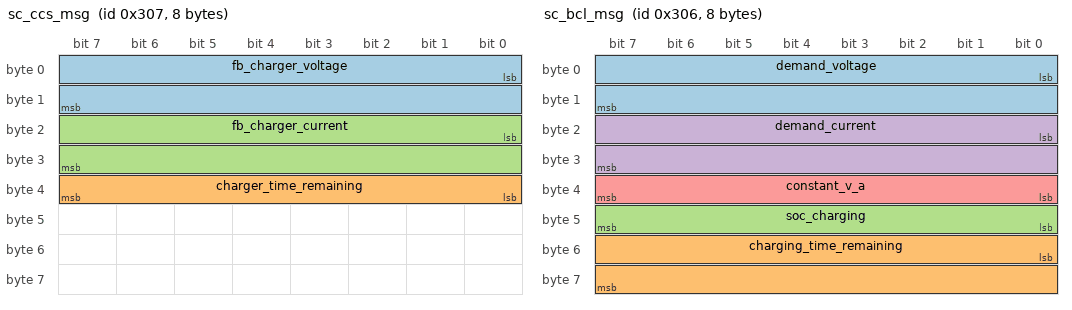
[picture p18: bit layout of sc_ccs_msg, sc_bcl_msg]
BO_ 775 sc_ccs_msg: 8 Vector__XXX
 SG_ fb_charger_voltage : 0|16@1+ (0.1,0) [0|6553.5] "" Vector__XXX
 SG_ charger_time_remaining : 32|8@1+ (1,0) [0|255] "" Vector__XXX
 SG_ fb_charger_current : 16|16@1+ (0.1,-40) [6153.5|4294966896] "" Vector__XXX

BO_ 774 sc_bcl_msg: 8 Vector__XXX
 SG_ demand_voltage : 0|16@1+ (0.1,0) [0|6553.5] "" Vector__XXX
 SG_ charging_time_remaining : 48|16@1+ (1,0) [0|255] "" Vector__XXX
 SG_ soc_charging : 40|8@1+ (1,0) [0|255] "" Vector__XXX
 SG_ demand_current : 16|16@1+ (0.1,-40) [6153.5|4294966896] "" Vector__XXX
 SG_ constant_v_a : 32|8@1+ (1,0) [0|255] "" Vector__XXX

BO_ 773 sc_cro_msg: 8 Vector__XXX
 SG_ charger_ready : 0|8@1+ (1,0) [0|255] "" Vector__XXX

BO_ 772 sc_bro_msg: 8 Vector__XXX
 SG_ bms_ready_to_charge : 0|8@1+ (1,0) [0|255] "" Vector__XXX

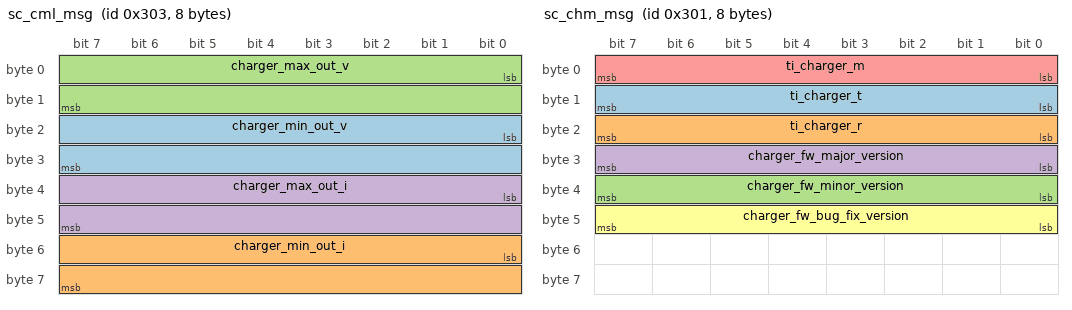
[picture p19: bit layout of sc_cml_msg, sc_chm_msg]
BO_ 771 sc_cml_msg: 8 Vector__XXX
 SG_ charger_min_out_v : 16|16@1+ (0.1,0) [0|6553.5] "" Vector__XXX
 SG_ charger_min_out_i : 48|16@1+ (0.1,-40) [6153.5|4294966896] "" Vector__XXX
 SG_ charger_max_out_v : 0|16@1+ (0.1,0) [0|6553.5] "" Vector__XXX
 SG_ charger_max_out_i : 32|16@1+ (0.1,-40) [6153.5|4294966896] "" Vector__XXX

BO_ 770 sc_bhm_msg: 8 Vector__XXX
 SG_ bms_fw_minor_version : 8|8@1+ (1,0) [0|255] "" Vector__XXX
 SG_ bms_fw_major_version : 0|8@1+ (1,0) [0|255] "" Vector__XXX
 SG_ bms_fw_bug_fix_version : 16|8@1+ (1,0) [0|255] "" Vector__XXX

BO_ 769 sc_chm_msg: 8 Vector__XXX
 SG_ ti_charger_t : 8|8@1+ (1,0) [0|255] "" Vector__XXX
 SG_ ti_charger_r : 16|8@1+ (1,0) [0|255] "" Vector__XXX
 SG_ charger_fw_minor_version : 32|8@1+ (1,0) [0|255] "" Vector__XXX
 SG_ charger_fw_major_version : 24|8@1+ (1,0) [0|255] "" Vector__XXX
 SG_ ti_charger_m : 0|8@1+ (1,0) [0|255] "" Vector__XXX
 SG_ charger_fw_bug_fix_version : 40|8@1+ (1,0) [0|255] "" Vector__XXX

CM_ BO_ 3221225472 "This is a message for not used signals, created by Vector CANdb++ DBC OLE DB Provider.";
BA_DEF_  "BusType" STRING ;
BA_DEF_DEF_  "BusType" "";
BA_ "BusType" "CAN";
SIG_VALTYPE_ 2415920755 md_cycle_count : 1;
SIG_VALTYPE_ 2415920755 md_soc : 1;
